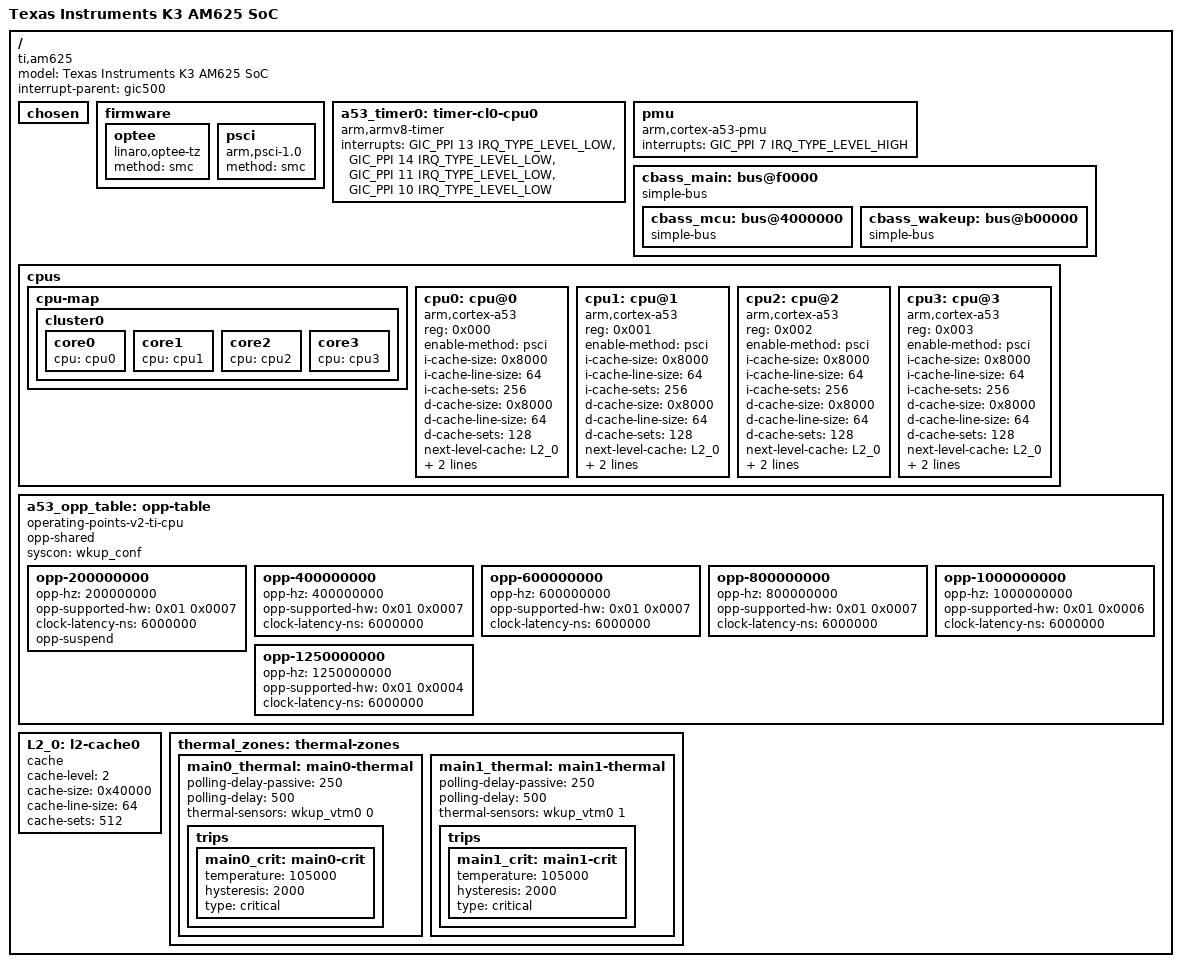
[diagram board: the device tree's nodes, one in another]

#include <dt-bindings/gpio/gpio.h>
#include <dt-bindings/interrupt-controller/irq.h>
#include <dt-bindings/interrupt-controller/arm-gic.h>
#include <dt-bindings/soc/ti,sci_pm_domain.h>
#include <dt-bindings/thermal/thermal.h>


#include "k3-pinctrl.h"

/ {
	
	
	model = "Texas Instruments K3 AM625 SoC";
	compatible = "ti,am625";
	interrupt-parent = <&gic500>;
	#address-cells = <2>;
	#size-cells = <2>;

	chosen { };

	firmware {
		optee {
			compatible = "linaro,optee-tz";
			method = "smc";
		};

		psci: psci {
			compatible = "arm,psci-1.0";
			method = "smc";
		};
	};

	a53_timer0: timer-cl0-cpu0 {
		compatible = "arm,armv8-timer";
		interrupts = <GIC_PPI 13 IRQ_TYPE_LEVEL_LOW>, /* cntpsirq */
			     <GIC_PPI 14 IRQ_TYPE_LEVEL_LOW>, /* cntpnsirq */
			     <GIC_PPI 11 IRQ_TYPE_LEVEL_LOW>, /* cntvirq */
			     <GIC_PPI 10 IRQ_TYPE_LEVEL_LOW>; /* cnthpirq */
	};

	pmu: pmu {
		compatible = "arm,cortex-a53-pmu";
		interrupts = <GIC_PPI 7 IRQ_TYPE_LEVEL_HIGH>;
	};

	cbass_main: bus@f0000 {
		compatible = "simple-bus";
		#address-cells = <2>;
		#size-cells = <2>;

		ranges = <0x00 0x000f0000 0x00 0x000f0000 0x00 0x00030000>, /* Main MMRs */
			 <0x00 0x00420000 0x00 0x00420000 0x00 0x00001000>, /* ESM0 */
			 <0x00 0x00600000 0x00 0x00600000 0x00 0x00001100>, /* GPIO */
			 <0x00 0x00703000 0x00 0x00703000 0x00 0x00000200>, /* USB0 debug trace */
			 <0x00 0x0070c000 0x00 0x0070c000 0x00 0x00000200>, /* USB1 debug trace */
			 <0x00 0x00a40000 0x00 0x00a40000 0x00 0x00000800>, /* Timesync router */
			 <0x00 0x01000000 0x00 0x01000000 0x00 0x01b28400>, /* First peripheral window */
			 <0x00 0x08000000 0x00 0x08000000 0x00 0x00200000>, /* Main CPSW */
			 <0x00 0x0e000000 0x00 0x0e000000 0x00 0x01d20000>, /* Second peripheral window */
			 <0x00 0x0fd00000 0x00 0x0fd00000 0x00 0x00020000>, /* GPU */
			 <0x00 0x20000000 0x00 0x20000000 0x00 0x0a008000>, /* Third peripheral window */
			 <0x00 0x30040000 0x00 0x30040000 0x00 0x00080000>, /* PRUSS-M */
			 <0x00 0x30101000 0x00 0x30101000 0x00 0x00010100>, /* CSI window */
			 <0x00 0x30200000 0x00 0x30200000 0x00 0x00010000>, /* DSS */
			 <0x00 0x30300000 0x00 0x30300000 0x00 0x00001000>, /* MCRC */
			 <0x00 0x31000000 0x00 0x31000000 0x00 0x00050000>, /* USB0 DWC3 Core window */
			 <0x00 0x31100000 0x00 0x31100000 0x00 0x00050000>, /* USB1 DWC3 Core window */
			 <0x00 0x40900000 0x00 0x40900000 0x00 0x00030000>, /* SA3UL */
			 <0x00 0x43600000 0x00 0x43600000 0x00 0x00010000>, /* SA3 sproxy data */
			 <0x00 0x44043000 0x00 0x44043000 0x00 0x00000fe0>, /* TI SCI DEBUG */
			 <0x00 0x44860000 0x00 0x44860000 0x00 0x00040000>, /* SA3 sproxy config */
			 <0x00 0x48000000 0x00 0x48000000 0x00 0x06400000>, /* DMSS */
			 <0x00 0x60000000 0x00 0x60000000 0x00 0x08000000>, /* FSS0 DAT1 */
			 <0x00 0x70000000 0x00 0x70000000 0x00 0x00010000>, /* OCSRAM */
			 <0x01 0x00000000 0x01 0x00000000 0x00 0x00310000>, /* A53 PERIPHBASE */
			 <0x05 0x00000000 0x05 0x00000000 0x01 0x00000000>, /* FSS0 DAT3 */
			 <0x00 0x3b000000 0x00 0x3b000000 0x00 0x00000400>, /* GPMC0_CFG */
			 <0x00 0x50000000 0x00 0x50000000 0x00 0x08000000>, /* GPMC0 DATA */

			 /* MCU Domain Range */
			 <0x00 0x04000000 0x00 0x04000000 0x00 0x01ff1400>,

			 /* Wakeup Domain Range */
			 <0x00 0x00b00000 0x00 0x00b00000 0x00 0x00002400>, /* VTM */
			 <0x00 0x2b000000 0x00 0x2b000000 0x00 0x00300400>,
			 <0x00 0x43000000 0x00 0x43000000 0x00 0x00020000>,
			 <0x00 0x78000000 0x00 0x78000000 0x00 0x00008000>, /* DM R5 ATCM*/
			 <0x00 0x78100000 0x00 0x78100000 0x00 0x00008000>; /* DM R5 BTCM*/

		cbass_mcu: bus@4000000 {
			compatible = "simple-bus";
			#address-cells = <2>;
			#size-cells = <2>;
			ranges = <0x00 0x04000000 0x00 0x04000000 0x00 0x01ff1400>; /* Peripheral window */
		};

		cbass_wakeup: bus@b00000 {
			compatible = "simple-bus";
			#address-cells = <2>;
			#size-cells = <2>;
			ranges = <0x00 0x00b00000 0x00 0x00b00000 0x00 0x00002400>, /* VTM */
				 <0x00 0x2b000000 0x00 0x2b000000 0x00 0x00300400>, /* Peripheral Window */
				 <0x00 0x43000000 0x00 0x43000000 0x00 0x00020000>,
				 <0x00 0x78000000 0x00 0x78000000 0x00 0x00008000>, /* DM R5 ATCM*/
				 <0x00 0x78100000 0x00 0x78100000 0x00 0x00008000>; /* DM R5 BTCM*/
		};
	};

	cpus {
		#address-cells = <1>;
		#size-cells = <0>;

		cpu-map {
			cluster0: cluster0 {
				core0 {
					cpu = <&cpu0>;
				};

				core1 {
					cpu = <&cpu1>;
				};

				core2 {
					cpu = <&cpu2>;
				};

				core3 {
					cpu = <&cpu3>;
				};
			};
		};

		cpu0: cpu@0 {
			compatible = "arm,cortex-a53";
			reg = <0x000>;
			device_type = "cpu";
			enable-method = "psci";
			i-cache-size = <0x8000>;
			i-cache-line-size = <64>;
			i-cache-sets = <256>;
			d-cache-size = <0x8000>;
			d-cache-line-size = <64>;
			d-cache-sets = <128>;
			next-level-cache = <&L2_0>;
			operating-points-v2 = <&a53_opp_table>;
			clocks = <&k3_clks 135 0>;
		};

		cpu1: cpu@1 {
			compatible = "arm,cortex-a53";
			reg = <0x001>;
			device_type = "cpu";
			enable-method = "psci";
			i-cache-size = <0x8000>;
			i-cache-line-size = <64>;
			i-cache-sets = <256>;
			d-cache-size = <0x8000>;
			d-cache-line-size = <64>;
			d-cache-sets = <128>;
			next-level-cache = <&L2_0>;
			operating-points-v2 = <&a53_opp_table>;
			clocks = <&k3_clks 136 0>;
		};

		cpu2: cpu@2 {
			compatible = "arm,cortex-a53";
			reg = <0x002>;
			device_type = "cpu";
			enable-method = "psci";
			i-cache-size = <0x8000>;
			i-cache-line-size = <64>;
			i-cache-sets = <256>;
			d-cache-size = <0x8000>;
			d-cache-line-size = <64>;
			d-cache-sets = <128>;
			next-level-cache = <&L2_0>;
			operating-points-v2 = <&a53_opp_table>;
			clocks = <&k3_clks 137 0>;
		};

		cpu3: cpu@3 {
			compatible = "arm,cortex-a53";
			reg = <0x003>;
			device_type = "cpu";
			enable-method = "psci";
			i-cache-size = <0x8000>;
			i-cache-line-size = <64>;
			i-cache-sets = <256>;
			d-cache-size = <0x8000>;
			d-cache-line-size = <64>;
			d-cache-sets = <128>;
			next-level-cache = <&L2_0>;
			operating-points-v2 = <&a53_opp_table>;
			clocks = <&k3_clks 138 0>;
		};
	};

	a53_opp_table: opp-table {
		compatible = "operating-points-v2-ti-cpu";
		opp-shared;
		syscon = <&wkup_conf>;

		opp-200000000 {
			opp-hz = /bits/ 64 <200000000>;
			opp-supported-hw = <0x01 0x0007>;
			clock-latency-ns = <6000000>;
			opp-suspend;
		};

		opp-400000000 {
			opp-hz = /bits/ 64 <400000000>;
			opp-supported-hw = <0x01 0x0007>;
			clock-latency-ns = <6000000>;
		};

		opp-600000000 {
			opp-hz = /bits/ 64 <600000000>;
			opp-supported-hw = <0x01 0x0007>;
			clock-latency-ns = <6000000>;
		};

		opp-800000000 {
			opp-hz = /bits/ 64 <800000000>;
			opp-supported-hw = <0x01 0x0007>;
			clock-latency-ns = <6000000>;
		};

		opp-1000000000 {
			opp-hz = /bits/ 64 <1000000000>;
			opp-supported-hw = <0x01 0x0006>;
			clock-latency-ns = <6000000>;
		};

		opp-1250000000 {
			opp-hz = /bits/ 64 <1250000000>;
			opp-supported-hw = <0x01 0x0004>;
			clock-latency-ns = <6000000>;
		};
	};

	L2_0: l2-cache0 {
		compatible = "cache";
		cache-level = <2>;
		cache-size = <0x40000>;
		cache-line-size = <64>;
		cache-sets = <512>;
	};

	thermal_zones: thermal-zones {
	main0_thermal: main0-thermal {
		polling-delay-passive = <250>; /* milliseconds */
		polling-delay = <500>; /* milliseconds */
		thermal-sensors = <&wkup_vtm0 0>;

		trips {
			main0_crit: main0-crit {
				temperature = <105000>; /* milliCelsius */
				hysteresis = <2000>; /* milliCelsius */
				type = "critical";
			};
		};
	};

	main1_thermal: main1-thermal {
		polling-delay-passive = <250>; /* milliseconds */
		polling-delay = <500>; /* milliseconds */
		thermal-sensors = <&wkup_vtm0 1>;

		trips {
			main1_crit: main1-crit {
				temperature = <105000>; /* milliCelsius */
				hysteresis = <2000>; /* milliCelsius */
				type = "critical";
			};
		};
	};
};
};

/* Now include the peripherals for each bus segments */
#include "myd-y62x-main.dtsi"
#include "myd-y62x-mcu.dtsi"
#include "myd-y62x-wakeup.dtsi"
